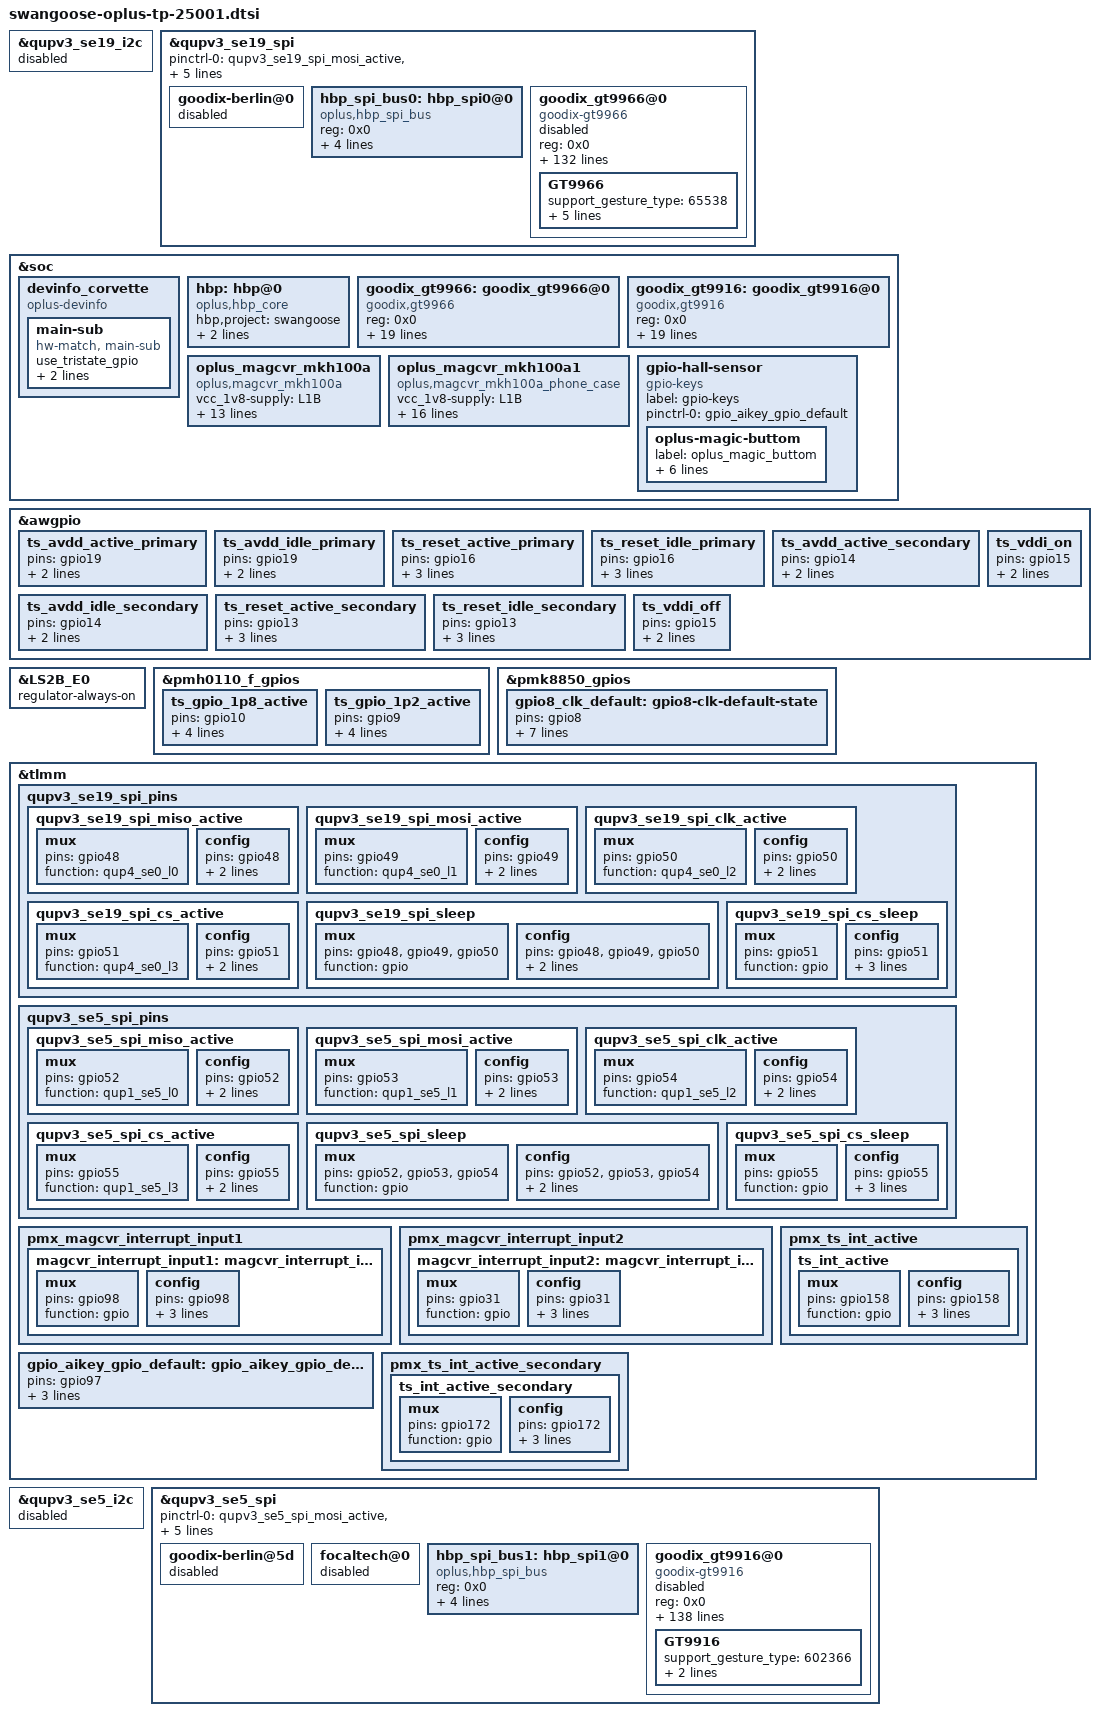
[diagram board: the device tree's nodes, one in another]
#include <dt-bindings/clock/qcom,gcc-sun.h>
#include <dt-bindings/clock/qcom,rpmh.h>

&qupv3_se19_i2c {
	status = "disabled";
};
&qupv3_se19_spi{
	/delete-property/ pinctrl-0;
	/delete-property/ pinctrl-1;
	pinctrl-0 = <&qupv3_se19_spi_mosi_active>, <&qupv3_se19_spi_miso_active>,
				<&qupv3_se19_spi_clk_active>, <&qupv3_se19_spi_cs_active>;
	pinctrl-1 = <&qupv3_se19_spi_sleep>, <&qupv3_se19_spi_cs_sleep>;
};

&soc {
	devinfo_corvette {
		compatible = "oplus-devinfo";

		main-sub {
			use_tristate_gpio;
			compatible = "hw-match, main-sub";
			aboard-patterns = <0 0 1>;	/*0[high-resistance] 1[pull-down] 2[pull-up]*/
			/*main board*/
			match-projects = <25001 25002 25201>;
		};
	};

	hbp:hbp@0 {
		compatible = "oplus,hbp_core";
		hbp,project = "swangoose";
		hbp,panels = <2>;
		hbp,devices = <&goodix_gt9966 &goodix_gt9916>;
	};

	goodix_gt9966:goodix_gt9966@0 {
		compatible = "goodix,gt9966";
		reg = <0x0>;
		status = "okay";
		device,chip_name = "gt9966";
		device,id = <0>;
		device,resolution = <35968 39680>;

		/* Interrupt && Irq-gpio */
		irq-gpio = <&tlmm 158 0x2002>;
		interrupt-parent = <&tlmm>;
		interrupts = <158 0x2002>;

		/*cs active state, not used now*/
		spi,cs_active = <0>;

		pinctrl-names = "default",
			"ts_avdd_on",
			"ts_avdd_off",
			"ts_reset_active",
			"ts_reset_idle",
			"ts_vddi_on",
			"ts_vddi_off";
		pinctrl-0 = <&ts_int_active &pmh0101_bidir_lvl_shifter2_active &gpio8_clk_default>;
		pinctrl-1 = <&ts_avdd_active_primary>;
		pinctrl-2 = <&ts_avdd_idle_primary>;
		pinctrl-3 = <&ts_reset_active_primary>;
		pinctrl-4 = <&ts_reset_idle_primary>;
		pinctrl-5 = <&ts_vddi_on>;
		pinctrl-6 = <&ts_vddi_off>;

		/*power config*/

		pen_support;
		/*clk*/
		clocks = <&rpmhcc RPMH_DIV_CLK1>;
		clock-names = "bb_clk4";
		/*bus config*/
		device,attached_bus = <&hbp_spi_bus0>;
	};

	goodix_gt9916:goodix_gt9916@0 {
		compatible = "goodix,gt9916";
		reg = <0x0>;
		status = "okay";
		device,chip_name = "gt9916";
		device,id = <1>;
		device,resolution = <18240 41856>;

		/* Interrupt && Irq-gpio */
		irq-gpio = <&tlmm 172 0x2002>;
 		interrupt-parent = <&tlmm>;
		interrupts = <172 0x2002>;

		/*cs active state, not used now*/
		spi,cs_active = <0>;

		pinctrl-names = "default",
			"ts_avdd_on",
			"ts_avdd_off",
			"ts_reset_active",
			"ts_reset_idle",
			"ts_vddi_on",
			"ts_vddi_off";
		pinctrl-0 = <&ts_int_active_secondary &ts_gpio_1p8_active &ts_gpio_1p2_active>;
		pinctrl-1 = <&ts_avdd_active_secondary>;
		pinctrl-2 = <&ts_avdd_idle_secondary>;
		pinctrl-3 = <&ts_reset_active_secondary>;
		pinctrl-4 = <&ts_reset_idle_secondary>;
		pinctrl-5 = <&ts_vddi_on>;
		pinctrl-6 = <&ts_vddi_off>;

		/*power config*/

		pen_support;
		fp_grip_support;
		/*bus config*/
		/*clk*/
		clocks = <&rpmhcc RPMH_DIV_CLK1>;
		clock-names = "bb_clk4";
		device,attached_bus = <&hbp_spi_bus1>;
	};
};

&awgpio {
	ts_avdd_active_primary:ts_avdd_active_primary{
		pins = "gpio19";
		drive-strength = <0>;
		output-high;
	};

	ts_avdd_idle_primary:ts_avdd_idle_primary{
		pins = "gpio19";
		drive-strength = <0>;
		output-low;
	};

	ts_reset_active_primary:ts_reset_active_primary{
		pins = "gpio16";
		drive-strength = <0>;
		output-high;
		bias-disable;
	};

	ts_reset_idle_primary:ts_reset_idle_primary{
		pins = "gpio16";
		drive-strength = <0>;
		output-low;
		bias-disable;
	};

	ts_avdd_active_secondary:ts_avdd_active_secondary{
		pins = "gpio14";
		drive-strength = <0>;
		output-high;
	};

	ts_avdd_idle_secondary:ts_avdd_idle_secondary{
		pins = "gpio14";
		drive-strength = <0>;
		output-low;
	};

	ts_reset_active_secondary:ts_reset_active_secondary{
		pins = "gpio13";
		drive-strength = <0>;
		output-high;
		bias-disable;
	};

	ts_reset_idle_secondary:ts_reset_idle_secondary{
		pins = "gpio13";
		drive-strength = <0>;
		output-low;
		bias-disable;
	};

	ts_vddi_on:ts_vddi_on{
		pins = "gpio15";
		drive-strength = <0>;
		output-high;
	};

	ts_vddi_off:ts_vddi_off{
		pins = "gpio15";
		drive-strength = <0>;
		output-low;
	};
};

&LS2B_E0 {
	regulator-always-on;
};

&pmh0110_f_gpios {
	ts_gpio_1p8_active: ts_gpio_1p8_active {
		pins = "gpio10";
		function = "paired";
		input-enable;
		output-disable;
		power-source = <1>; /* 1.8v */
	};

	ts_gpio_1p2_active: ts_gpio_1p2_active {
		pins = "gpio9";
		function = "paired";
		input-disable;
		output-enable;
		power-source = <2>; /* 1.2v */
	};
};

&pmk8850_gpios{
	gpio8_clk_default: gpio8-clk-default-state {
		pins = "gpio8";
		function = "func2";
		input-disable;
		bias-disable;
		output-enable;
		output-low;
		power-source = <0>; /* 1.8 V */
		qcom,drive-strength = <2>;
	};
};

&qupv3_se19_spi {
	status = "ok";

	goodix-berlin@0 {
		status = "disabled";
	};

	hbp_spi_bus0:hbp_spi0@0 {
		compatible = "oplus,hbp_spi_bus";
		reg = <0x0>;
		status = "okay";

		spi-max-frequency = <19000000>;
		bus,spi-mode = <0>;
		bus,rx-dummy = <0>;
		bus,tx-dummy = <0>;
	};

	goodix_gt9966@0 {
		status = "disabled";
		compatible = "goodix-gt9966";
		reg = <0x0>;
		spi-max-frequency = <4500000>;
		qcom,rt;
		chip-num = <1>;
		chip-name = "GT9966";

		/* Interrupt && Irq-gpio */
		interrupt-parent = <&tlmm>;
		interrupts = <158 0x2002>;

		/* Other HW Resource1 */
		irq-gpio = <&tlmm 158 0x2002>;
		reset-gpio = <&awgpio 16 0>;
		pinctrl-names = "default";
		pinctrl-0 = <&ts_int_active &pmh0101_bidir_lvl_shifter2_active &gpio8_clk_default>;


		/* Power Config */
		enable2v8_gpio = <&awgpio 19 0>;
		enable1v8_gpio = <&awgpio 15 0>;

		touchpanel,max-num-support = <10>;
		touchpanel,tx-rx-num = <38 42>;
		earsense,tx-rx-num = <38 42>;
		touchpanel,panel-coords = <22480 24800>;
		touchpanel,display-coords = <2248 2480 >;
		touchpanel,touchmajor-limit = <128 216>;
		touchpanel,single-optimized-time = <8>;
		touchpanel,high-frame-rate-time = <60>;

		touchpanel,pen-tx-rx-num = <38 42>;
		touchpanel,pen-panel-coords = <22480 24800>;
		touchpanel,pen-max-pressure = <4096>;
		touchpanel,pen-max-tilt = <60 60>;
		touchpanel,msecs-to-jiffies-time = <100>;

		touchpanel,smooth-level = <0 47 45 59 57 131>; /* HighByte:previoueFrame; LowByte:currentFrame */
		//touchpanel,smooth-level-charging = <0 47 45 59 57 131>;
		touchpanel,sensitive-level = <0 90 70 60 57 131>;
		project_id = <25001>;
		vid_len = <2>;
		touchpanel,tp-index = <0>;
		panel_type = <8>;
		firmware_name = "AC205";
		// type of tp_dev ,TP-SAMSUNG = 8;
		platform_support_project = <25001 25002 25201>;
		platform_support_project_dir = <25001 25001 25001 25001>;
		platform_support_project_commandline = "mdss_dsi_panel_AC306_P_1_A0002_dsc_cmd";

		prevention,curved_screen_V2;
		prevention,grip_disable_level = <6>;
		prevention,updelay_time_ms = <30>;
		prevention,makeup_cnt_weight = <5 1 2 2 2>;
		prevention,large_corner_range = <1200 3000>;
		prevention,large_corner_judge_condition = <300 100 1000 7 7>;
		prevention,trx_reject_condition = <9 7 5>;
		prevention,trx_strict_reject_condition = <3 1 1>;
		prevention,large_judge_time_ms = <500 50 100>;
		prevention,large_exit_condition = <8 8 2>;
		prevention,single_channel_width = <320 320>;
		prevention,normal_tap_condition = <10 350>;
		prevention,long_edge_condition = <70 120 40 80>;
		prevention,long_strict_edge_condition = <50 25>;
		prevention,long_fingerhold_condition = <70 6 4 4>;
		prevention,short_edge_condition = <250 90 180 80>;
		prevention,short_strict_edge_condition = <160 60>;
		prevention,large_strict_exit_condition = <4 4>;
		prevention,top_corner_config = <500 1500 300>;
		prevention,edge_swipe_config = <300 1000>;

		prevention,curved_screen_V4;
		prevention,long_eliminate_point_type = <2 14400 10560 300 31680 300 1>;
		prevention,long_fingerhold_condition2 = <650 2000 0 0>;
		prevention,top_corner_config2 = <3 80 600 1500 0>;
		prevention,hor_long_top_corner_config = <350 2270 0 0>;
		prevention,top_middle_config = <14400 1000 1000 0>;
		prevention,corner_eliminate_point_type = <0 1380 2280 1>;
		prevention,finger_hold_differ_size = <1 0 400 300>;
		prevention,finger_hold_max_rx_exit_distance = <5 350 2300>;
		prevention,max_rx_exit_distance = <1 5 150 350 2000>;
		prevention,dynamic_finger_hold_exit_distance = <1 350 2300 450>;
		prevention,edge_sliding_matched_support = <1 150 3 0>;
		//grip v4.2 reclining mode
		prevention,reclining_mode_support = <1>;
		prevention,long_eliminate_point_type_recli = <2 12400 9240 240 27720 500 1>;
		prevention,finger_hold_differ_size_recli = <1 0 400 400>;
		prevention,finger_hold_max_rx_exit_distance_recli = <5 350 2300>;
		prevention,max_rx_exit_distance_recli = <1 5 100 350 2300>;
		prevention,dynamic_finger_hold_exit_distance_recli = <1 350 2300 450>;
		prevention,edge_sliding_matched_support_recli = <1 150 3 0>;
		prevention,long_edge_condition_recli = <179 90 120 80>;
		/*for grip 4.3*/
		prevention,curved_screen_v4_3;
		prevention,corner_point_edge_percent_thd = <1600 1 30 32 1>;
		prevention,corner_point_edge_percent_thd2 = <40 3 20 0 0>;
		prevention,point_stability_judgment_check = <1 1 0 0 0>;
		prevention,point_corner_er_min_limit_check = <3 3 0 0 1>;
		prevention,one_frame_down_check_support = <1>;

		black_gesture_support;
		pressure_report_support;
		charger_pump_support;
		game_switch_support;
		smart_gesture_support;
		spi_port_support;
		suspend_work_support;
		fw_update_app_support;
		//fingerprint_underscreen_support;
		//freq_hop_simulate_support;
		report_flow_unlock_support;
		//screenoff_fingerprint_info_support;
		irq_need_dev_resume_ok;
		//enable_point_auto_change;
		//report_rate_white_list_support;
		kernel_grip_support;
		exception_upload_support;
		//grip_no_driver_support;
		health_monitor_support;
		black_gesture_indep_support;
		//algorithm_support;
		snr_read_support;
		//touchpanel,get_motor_coord = <0 370 70>;
		sportify_aod_gesture_support;
		temperature_detect_shellback_support;
		pen_support;
		pen_support_opp;
		no_need_osctest;
		bus_ready_check_support;
		tp_lcd_suspend_in_lp_support;
		//fpga_spi_agg_support;
		tp_data_record_support;
		input_timestamp_in_top_irq_support;
		/*
		 *Virtual Key Config:
		 *1:touchpanel,button-type: <virtualkey_type  supportted_button-map>
		 *virtualkey_type:
		 *Type 1: using board_properties
		 *Type 2: using same IC (button zone&& touch zone are seprate)
		 *Type 3: using diffrent IC (button zone&& touch zone are seprate)
		 *Type 4: No need of virtual key process
		 *supportted_button-map:select|menu|home|back
		 *
		 *2:touchpanel,button-map
		 *type (X1,Y1)(X2,Y2)(X3,Y3)(Width_X,Hight_Y)--Only when button-type is 0
		 */
		touchpanel,button-type = <4>;
		touchpanel.button-TRx = <0 0>;

		GT9966 {
			support_gesture_type = <65538>;
			support_disp_rate = <60 120>;
			pen_osc_frequency = <64>; /*16m or 64m osc clk for factory test*/
			need_change_clk_name = "SAMSUNG_CLK";
			SAMSUNG_CLK = <16>;
			hardware_trx_direction = <1>;/* 0:left,right:tx up,down:rx
							1:left,right:rx up,down:tx
							'when usb port faces down' */
		};
	};

};

&tlmm {
	qupv3_se19_spi_pins: qupv3_se19_spi_pins {
		qupv3_se19_spi_miso_active: qupv3_se19_spi_miso_active {
			mux {
				pins = "gpio48";
				function = "qup4_se0_l0";
			};

			config {
				pins = "gpio48";
				drive-strength = <4>;
				bias-disable;
			};
		};

		qupv3_se19_spi_mosi_active: qupv3_se19_spi_mosi_active {
			mux {
				pins = "gpio49";
				function = "qup4_se0_l1";
			};

			config {
				pins = "gpio49";
				drive-strength = <4>;
				bias-disable;
			};
		};

		qupv3_se19_spi_clk_active: qupv3_se19_spi_clk_active {
			mux {
				pins = "gpio50";
				function = "qup4_se0_l2";
			};

			config {
				pins = "gpio50";
				drive-strength = <4>;
				bias-disable;
			};
		};

		qupv3_se19_spi_cs_active: qupv3_se19_spi_cs_active {
			mux {
				pins = "gpio51";
				function = "qup4_se0_l3";
			};

			config {
				pins = "gpio51";
				drive-strength = <4>;
				bias-disable;
			};
		};

		qupv3_se19_spi_sleep: qupv3_se19_spi_sleep {
			mux {
				pins = "gpio48", "gpio49",
					"gpio50";
				function = "gpio";
			};

			config {
				pins = "gpio48", "gpio49",
					"gpio50";
				drive-strength = <2>;
				bias-disable;
			};
		};

		qupv3_se19_spi_cs_sleep: qupv3_se19_spi_cs_sleep {
			mux {
				pins = "gpio51";
				function = "gpio";
			};

			config {
				pins = "gpio51";
				drive-strength = <2>;
				bias-disable;
				output-high;
			};
		};
	};
};

&qupv3_se5_i2c {
		status = "disabled";
};

&qupv3_se5_spi{
	/delete-property/ pinctrl-0;
	/delete-property/ pinctrl-1;
	pinctrl-0 = <&qupv3_se5_spi_mosi_active>, <&qupv3_se5_spi_miso_active>,
				<&qupv3_se5_spi_clk_active>, <&qupv3_se5_spi_cs_active>;
	pinctrl-1 = <&qupv3_se5_spi_sleep>, <&qupv3_se5_spi_cs_sleep>;
};

&qupv3_se5_spi {
	status = "ok";

	goodix-berlin@5d {
		status = "disabled";
	};

	focaltech@0 {
		status = "disabled";
	};

	hbp_spi_bus1:hbp_spi1@0 {
		compatible = "oplus,hbp_spi_bus";
		reg = <0x0>;
		status = "okay";

		spi-max-frequency = <19000000>;
		bus,spi-mode = <0>;
		bus,rx-dummy = <0>;
		bus,tx-dummy = <0>;
	};

	goodix_gt9916@0{
		compatible = "goodix-gt9916";
		reg = <0x0>;
		chip-name = "GT9916";
		status = "disabled";
		spi-max-frequency = <4500000>;
		qcom,rt;

		/* Interrupt && Irq-gpio */
		irq-gpio = <&tlmm 172 0x2002>;
		interrupt-parent = <&tlmm>;
		interrupts = <172 0x2002>;

		/* Power Config */
		enable2v8_gpio = <&awgpio 14 0>;
		enable1v8_gpio = <&awgpio 15 0>;

		/* Other HW Resource */
		reset-gpio = <&awgpio 13 0>;

		pinctrl-names = "default";
		pinctrl-0 = <&ts_int_active_secondary &ts_gpio_1p8_active &ts_gpio_1p2_active>;

		touchpanel,max-num-support = <10>;
		touchpanel,tx-rx-num = <17 39>;
		earsense,tx-rx-num = <17 39>;
		touchpanel,panel-coords = <11400 26160>;
		touchpanel,display-coords = <1140 2616>;
		touchpanel,touchmajor-limit = <256 256>;
		touchpanel,curved-size = <45>;

		touchpanel,single-optimized-time = <8>;
		touchpanel,high-frame-rate-time = <60>;

		touchpanel,pen-tx-rx-num = <17 39>;
		touchpanel,pen-panel-coords = <11400 26160>;
		touchpanel,pen-max-pressure = <4096>;
		touchpanel,pen-max-tilt = <60 60>;
		touchpanel,msecs-to-jiffies-time = <100>;

		touchpanel,smooth-level = <0 95 115 135 165 205>;
		touchpanel,smooth-level-charging = <0 111 142 163 219 231>;
		touchpanel,sensitive-level = <0 90 70 60 40 31>;

		project_id = <25001>;
		vid_len = <2>;
		touchpanel,tp-index = <1>;
		panel_type = <7 3>; // type of tp_dev ,TP-BOE = 3 TP-TIANMA = 7;
		firmware_name = "AC205","AC205";
		platform_support_project = <25001 25002 25201>;
		platform_support_project_dir = <25001 25001 25001>;
		platform_support_project_commandline = "mdss_dsi_panel_AC140_S_3_A0014_dsc_cmd",
		                                       "mdss_dsi_panel_AC306_S_3_A0020_dsc_cmd";

		prevention,curved_screen_V2;
		prevention,grip_disable_level = <6>;
		prevention,updelay_time_ms = <30>;
		prevention,makeup_cnt_weight = <5 1 2 2 2>;
		prevention,large_corner_range = <1200 3000>;
		prevention,large_corner_judge_condition = <500 100 1000 7 7>;
		prevention,trx_reject_condition = <9 7 7>;
		prevention,trx_strict_reject_condition = <8 5 5>;
		prevention,large_judge_time_ms = <500 50 100>;
		prevention,large_exit_condition = <8 8 2>;
		prevention,single_channel_width = <320 320>;
		prevention,normal_tap_condition = <10 350>;
		prevention,long_edge_condition = <90 120 60 80>;
		prevention,long_strict_edge_condition = <50 25>;
		prevention,long_fingerhold_condition = <70 6 4 4>;
		prevention,short_edge_condition = <250 90 180 80>;
		prevention,short_strict_edge_condition = <160 60>;
		prevention,large_strict_exit_condition = <4 4>;
		prevention,top_corner_config = <500 1500 300>;
		prevention,edge_swipe_config = <300 1000>;

		prevention,curved_screen_V4;
		prevention,long_eliminate_point_type = <2 11160 8280 300 24840 300 1>;
		prevention,long_fingerhold_condition2 = <650 2000 0 0>;
		prevention,top_corner_config2 = <3 80 600 1500 0>;
		prevention,hor_long_top_corner_config = <350 2270 0 0>;
		prevention,top_middle_config = <11160 1000 1000 0>;
		prevention,corner_eliminate_point_type = <0 1380 2280 1>;
		prevention,finger_hold_differ_size = <1 0 300 300>;
		prevention,finger_hold_max_rx_exit_distance = <5 350 2300>;
		prevention,max_rx_exit_distance = <1 5 150 350 2000>;
		prevention,dynamic_finger_hold_exit_distance = <1 350 2300 450>;
		prevention,large_corner_judge_condition_ime = <300 0 0 0 0>;
		prevention,edge_sliding_matched_support = <1 150 3 0>;
		//grip v4.2 reclining mode
		prevention,reclining_mode_support = <1>;
		prevention,long_eliminate_point_type_recli = <2 12400 9240 240 27720 500 1>;
		prevention,finger_hold_differ_size_recli = <1 0 400 400>;
		prevention,finger_hold_max_rx_exit_distance_recli = <5 350 2300>;
		prevention,max_rx_exit_distance_recli = <1 5 100 350 2300>;
		prevention,dynamic_finger_hold_exit_distance_recli = <1 350 2300 450>;
		prevention,edge_sliding_matched_support_recli = <1 150 3 0>;
		prevention,long_edge_condition_recli = <179 90 120 80>;
		/*for grip 4.3*/
		prevention,curved_screen_v4_3;
		prevention,corner_point_edge_percent_thd = <1600 1 30 32 1>;
		prevention,corner_point_edge_percent_thd2 = <40 3 20 0 0>;
		prevention,point_stability_judgment_check = <1 1 0 0 0>;
		prevention,point_corner_er_min_limit_check = <3 5 0 0 1>;
		prevention,one_frame_down_check_support = <1>;

		black_gesture_support;
		pressure_report_support;
		charger_pump_support;
		game_switch_support;
		smart_gesture_support;
		spi_port_support;
		fw_update_app_support;
		suspend_work_support;
		//fingerprint_underscreen_support;
		//freq_hop_simulate_support;
		report_flow_unlock_support;
		//screenoff_fingerprint_info_support;
		irq_need_dev_resume_ok;
		//enable_point_auto_change;
		//report_rate_white_list_support;
		kernel_grip_support;
		exception_upload_support;
		//grip_no_driver_support;
		health_monitor_support;
		black_gesture_indep_support;
		//algorithm_support;
		snr_read_support;
		//touchpanel,get_motor_coord = <0 370 70>;
		sportify_aod_gesture_support;
		pen_support;
		pen_support_opp;
		no_need_osctest;
		palm_to_sleep_support;
		temperature_detect_shellback_support;
		bus_ready_check_support;
		tp_lcd_suspend_in_lp_support;
		//fpga_spi_agg_support;
		tp_data_record_support;
		input_timestamp_in_top_irq_support;
		fp_grip_support;
		/*
		 *Virtual Key Config:
		 *1:touchpanel,button-type: <virtualkey_type  supportted_button-map>
		 *virtualkey_type:
		 *Type 1: using board_properties
		 *Type 2: using same IC (button zone&& touch zone are seprate)
		 *Type 3: using diffrent IC (button zone&& touch zone are seprate)
		 *Type 4: No need of virtual key process
		 *supportted_button-map:select|menu|home|back
		 *
		 *2:touchpanel,button-map
		 *type (X1,Y1)(X2,Y2)(X3,Y3)(Width_X,Hight_Y)--Only when button-type is 0
		 */
		touchpanel,button-type = <4>;
		touchpanel.button-TRx = <0 0>;

		GT9916 {
			support_gesture_type = <602366>;
			support_disp_rate = <60 120>;
			pen_osc_frequency = <64>; /*16m or 64m osc clk for factory test*/
		};
	};

};

&tlmm {


	qupv3_se5_spi_pins: qupv3_se5_spi_pins {
		qupv3_se5_spi_miso_active: qupv3_se5_spi_miso_active {
			mux {
				pins = "gpio52";
				function = "qup1_se5_l0";
			};

			config {
				pins = "gpio52";
				drive-strength = <4>;
				bias-disable;
			};
		};

		qupv3_se5_spi_mosi_active: qupv3_se5_spi_mosi_active {
			mux {
				pins = "gpio53";
				function = "qup1_se5_l1";
			};

			config {
				pins = "gpio53";
				drive-strength = <4>;
				bias-disable;
			};
		};

		qupv3_se5_spi_clk_active: qupv3_se5_spi_clk_active {
			mux {
				pins = "gpio54";
				function = "qup1_se5_l2";
			};

			config {
				pins = "gpio54";
				drive-strength = <4>;
				bias-disable;
			};
		};

		qupv3_se5_spi_cs_active: qupv3_se5_spi_cs_active {
			mux {
				pins = "gpio55";
				function = "qup1_se5_l3";
			};

			config {
				pins = "gpio55";
				drive-strength = <4>;
				bias-disable;
			};
		};

		qupv3_se5_spi_sleep: qupv3_se5_spi_sleep {
			mux {
				pins = "gpio52", "gpio53",
					"gpio54";
				function = "gpio";
			};

			config {
				pins = "gpio52", "gpio53",
					"gpio54";
				drive-strength = <2>;
				bias-disable;
			};
		};

		qupv3_se5_spi_cs_sleep: qupv3_se5_spi_cs_sleep {
			mux {
				pins = "gpio55";
				function = "gpio";
			};

			config {
				pins = "gpio55";
				drive-strength = <2>;
				bias-disable;
				output-high;
			};
		};
	};
};

&soc {
	oplus_magcvr_mkh100a {
		status = "ok";
		compatible = "oplus,magcvr_mkh100a";
		vcc_1v8-supply = <&L1B>;
		// vcc_3v0-supply = <&mt6368_vio28>;
		// vdd_3v0_volt = <3100000>;
		interrupt-parent = <&tlmm>;
		interrupts = <98 0x02>;
		mag_irq_gpio = <&tlmm 98 0x2002>;
		pinctrl-names = "default";
		pinctrl-0 = <&magcvr_interrupt_input1>;
		// para config
		magcvr_detect_step = <50>;
		magcvr_farmax_th = <50>;
		magcvr_far_threshold = <150>;
		magcvr_far_noise_threshold = <125>;
		magcvr_irq_type = <4>;
		magcvr_index = <0>;
		no_need_calibration;
		// check_hrtimer_params = <200 5 300 5>;
		delay_time = <100>;
		is_gpio_mode = <1>;
	};
	oplus_magcvr_mkh100a1 {
		status = "ok";
		compatible = "oplus,magcvr_mkh100a_phone_case";
		vcc_1v8-supply = <&L1B>;
		// vcc_3v0-supply = <&mt6368_vio28>;
		// vdd_3v0_volt = <3100000>;
		interrupt-parent = <&tlmm>;
		interrupts = <31 0x02>;
		mag_irq_gpio = <&tlmm 31 0x2002>;
		pinctrl-names = "default";
		pinctrl-0 = <&magcvr_interrupt_input2>;
		// para config
		magcvr_detect_step = <50>;
		magcvr_farmax_th = <50>;
		magcvr_far_threshold = <150>;
		magcvr_far_noise_threshold = <125>;
		magcvr_irq_type = <4>;
		magcvr_index = <1>;
		linux,near-code = <740>;
		linux,far-code = <741>;
		pen_name = "pen";
		no_need_calibration;
		// check_hrtimer_params = <200 5 300 5>;
		delay_time = <100>;
		is_gpio_mode = <1>;
	};
};

&tlmm {
	pmx_magcvr_interrupt_input1 {
		magcvr_interrupt_input1: magcvr_interrupt_input-state {
			mux {
				pins = "gpio98";
				function = "gpio";
			};

			config {
				pins = "gpio98";
				drive-strength = <2>;
				bias-disable;
				input-enable;
			};
		};
	};
	pmx_magcvr_interrupt_input2 {
		magcvr_interrupt_input2: magcvr_interrupt_input-state {
			mux {
				pins = "gpio31";
				function = "gpio";
			};

			config {
				pins = "gpio31";
				drive-strength = <2>;
				bias-disable;
				input-enable;
			};
		};
	};
};

&soc {
	gpio-hall-sensor {
		compatible = "gpio-keys";
		label = "gpio-keys";
		status = "okay";
		pinctrl-0 = <&gpio_aikey_gpio_default>;
		pinctrl-names = "default";
		oplus-magic-buttom {
			label = "oplus_magic_buttom";
			gpios = <&tlmm 97 GPIO_ACTIVE_LOW>;
			linux,input-type = <EV_KEY>;
			linux,code = <735>; /* means: BTN_TRIGGER_HAPPY32 */
			linux,can-disable;
			gpio-key,wakeup;
			debounce-interval = <32>; /* standard debounce time 32ms */
		};
	};
};

&tlmm {
		gpio_aikey_gpio_default: gpio_aikey_gpio_default-state {
			pins = "gpio97";
			function = "gpio";
			drive-strength = <6>;
			bias-disable;
		};

		pmx_ts_int_active {
			ts_int_active: ts_int_active {
				mux {
					pins = "gpio158";
					function = "gpio";
				};

				config {
					pins = "gpio158";
					drive-strength = <2>;
					bias-disable;
					input-enable;
				};
			};
		};

		pmx_ts_int_active_secondary {
			ts_int_active_secondary: ts_int_active_secondary {
				mux {
					pins = "gpio172";
					function = "gpio";
				};

				config {
					pins = "gpio172";
					drive-strength = <2>;
					bias-disable;
					input-enable;
				};
			};
		};
};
